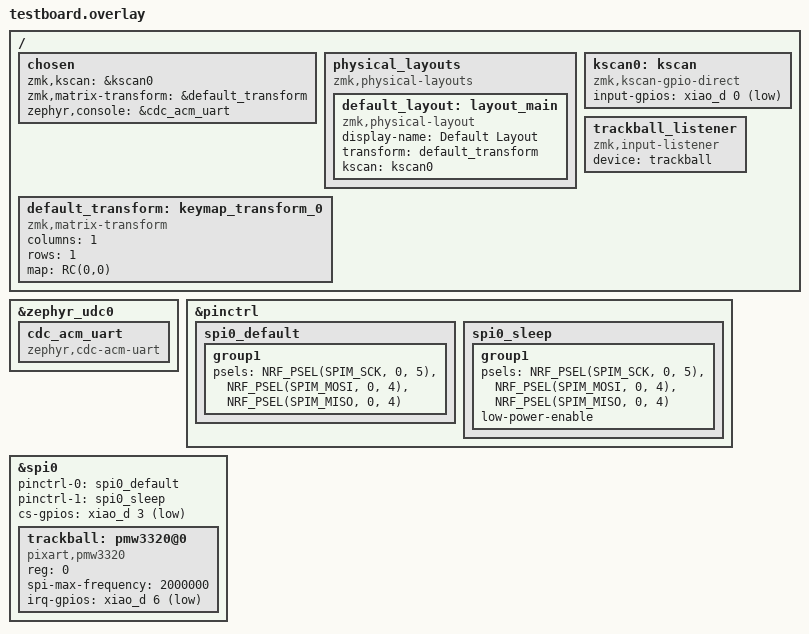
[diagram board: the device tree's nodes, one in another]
#include <dt-bindings/zmk/matrix_transform.h>
#include <physical_layouts.dtsi>
#include "testboard-layouts.dtsi"

/ {
    chosen {
        zmk,kscan = &kscan0;
        zmk,matrix-transform = &default_transform;
        zephyr,console = &cdc_acm_uart;
    };


    /* これが physical_layouts.c のエラーを直すための定義です */
    physical_layouts {
        compatible = "zmk,physical-layouts";
        default_layout: layout_main {
            compatible = "zmk,physical-layout";
            display-name = "Default Layout";
            transform = <&default_transform>;
            kscan = <&kscan0>;
        };
    };

    /* 最小限の行列定義 */
    default_transform: keymap_transform_0 {
        compatible = "zmk,matrix-transform";
        columns = <1>;
        rows = <1>;
        map = <RC(0,0)>;
    };

    /* ダミーの入力定義 */
    kscan0: kscan {
        compatible = "zmk,kscan-gpio-direct";
        input-gpios = <&xiao_d 0 (GPIO_ACTIVE_LOW | GPIO_PULL_UP)>;
    };
};

/* USBコントローラーに仮想シリアルポートを紐付ける */
&zephyr_udc0 {
    cdc_acm_uart: cdc_acm_uart {
        compatible = "zephyr,cdc-acm-uart";
    };
};


&pinctrl {
    spi0_default: spi0_default {
        group1 {
            psels = <NRF_PSEL(SPIM_SCK, 0, 5)>,
                    <NRF_PSEL(SPIM_MOSI, 0, 4)>,
                    <NRF_PSEL(SPIM_MISO, 0, 4)>;
        };
    };

    spi0_sleep: spi0_sleep {
        group1 {
            psels = <NRF_PSEL(SPIM_SCK, 0, 5)>,
                    <NRF_PSEL(SPIM_MOSI, 0, 4)>,
                    <NRF_PSEL(SPIM_MISO, 0, 4)>;
            low-power-enable;
        };
    };
};

&spi0 {
    status = "okay";
    pinctrl-0 = <&spi0_default>;
    pinctrl-1 = <&spi0_sleep>; // sleep用も指定
    pinctrl-names = "default", "sleep"; // "sleep"を追加
    cs-gpios = <&xiao_d 3 GPIO_ACTIVE_LOW>;

    trackball: pmw3320@0 {
        compatible = "pixart,pmw3320";
        reg = <0>;
        spi-max-frequency = <2000000>;
        irq-gpios = <&xiao_d 6 (GPIO_ACTIVE_LOW | GPIO_PULL_UP)>;
        status = "okay";
    };
};

/ {
    /* listener の compatible を zmk,input-listener に */
    trackball_listener {
        compatible = "zmk,input-listener";
        device = <&trackball>;
    };
};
